# CH32H417 register map
Vendor: WCH Ltd.; File version: 1.2
Registers are 32-bit, read-write, reset 0x0 unless marked. A register's access mark holds for its fields unless they carry their own. Offsets are from the block's base; [hi:lo] are bit positions; {n}, {i} and the like mark numbered series.

## EXTI
Base 0x40010400
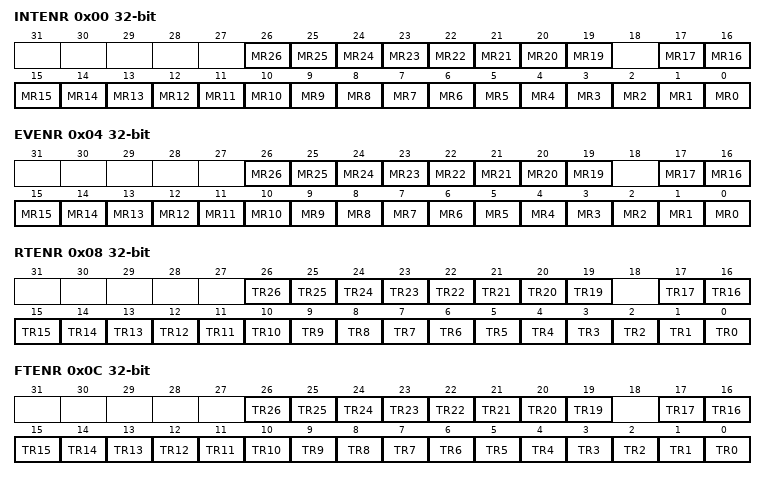
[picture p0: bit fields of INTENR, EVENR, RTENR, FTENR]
0x00 INTENR — Interrupt mask register (EXTI_INTENR)
  [n] MR{n} (n=19..26) — Interrupt Mask on line {n}
  [n] MR{n} (n=0..17) — Interrupt Mask on line {n}
0x04 EVENR — Event mask register (EXTI_EVENR)
  [n] MR{n} (n=19..26) — Event Mask on line {n}
  [n] MR{n} (n=0..17) — Event Mask on line {n}
0x08 RTENR — Rising Trigger selection register (EXTI_RTENR)
  [n] TR{n} (n=19..26) — Rising trigger event configuration of line {n}
  [n] TR{n} (n=0..17) — Rising trigger event configuration of line {n}
0x0C FTENR — Falling Trigger selection register (EXTI_FTENR)
  [n] TR{n} (n=19..26) — Falling trigger event configuration of line {n}
  [n] TR{n} (n=0..17) — Falling trigger event configuration of line {n}
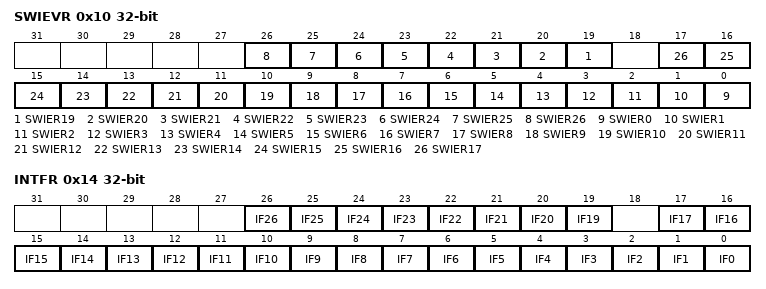
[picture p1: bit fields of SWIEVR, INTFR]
0x10 SWIEVR — Software interrupt event register (EXTI_SWIEVR)
  [n] SWIER{n} (n=19..26) — Software Interrupt on line {n}
  [n] SWIER{n} (n=0..17) — Software Interrupt on line {n}
0x14 INTFR — interrupt flag register (EXTI_INTFR)
  [n] IF{n} (n=19..26) — interrupt flag bit {n}
  [n] IF{n} (n=0..17) — interrupt flag bit {n}

## OPA — OPA configuration
Base 0x40017800
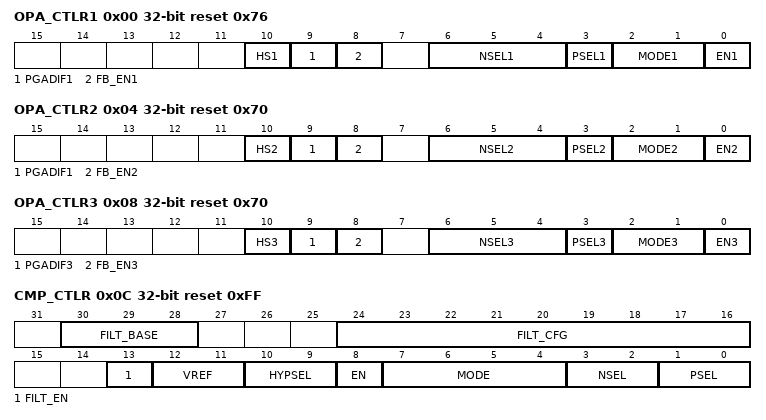
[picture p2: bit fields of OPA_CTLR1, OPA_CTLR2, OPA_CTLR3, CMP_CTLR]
0x00 OPA_CTLR1 reset 0x76 — OPA Control Register 1
  [10] HS1 — OPA1 high-speed mode enables
  [9] PGADIF1 — OPA1 is used with NSEL1 as PGA and the N-terminal is connected to OPA1_CHN1 (PA7)
  [8] FB_EN1 — OPA1's PGA mode feedback enable
  [6:4] NSEL1 — OPA1 Negative Channel Selection vs. PGA Gain Selection
  [3] PSEL1 — OPA1 Positive Channel Selection
  [2:1] MODE1 — OPA1 Output Channel Selection
  [0] EN1 — OPA1 enable
0x04 OPA_CTLR2 reset 0x70 — OPA Control Register 2
  [10] HS2 — OPA2 high-speed mode enables
  [9] PGADIF1 — OPA2 is used with NSEL1 as PGA and the N-terminal is connected to OPA2_CHN1 (PA7)
  [8] FB_EN2 — OPA2's PGA mode feedback enable
  [6:4] NSEL2 — OPA2 Negative Channel Selection vs. PGA Gain Selection
  [3] PSEL2 — OPA2 Positive Channel Selection
  [2:1] MODE2 — OPA2 Output Channel Selection
  [0] EN2 — OPA2 enable
0x08 OPA_CTLR3 reset 0x70 — OPA Control Register 3
  [10] HS3 — OPA3 high-speed mode enables
  [9] PGADIF3 — OPA3 is used with NSEL1 as PGA and the N-terminal is connected to OPA3_CHN1 (PA7)
  [8] FB_EN3 — OPA3's PGA mode feedback enable
  [6:4] NSEL3 — OPA3 Negative Channel Selection vs. PGA Gain Selection
  [3] PSEL3 — OPA3 Positive Channel Selection
  [2:1] MODE3 — OPA3 Output Channel Selection
  [0] EN3 — OPA3 enable
0x0C CMP_CTLR reset 0xFF — CMP Control Registers
  [30:28] FILT_BASE — CMP filtering sampling time base configuration
  [24:16] FILT_CFG — CMP filter sampling interval configuration
  [13] FILT_EN — CMP Digital Filtering Enable
  [12:11] VREF — CMP Internal Bias Voltage Selector
  [10:9] HYPSEL — CMP hysteresis voltage selector
  [8] EN — CMP enables
  [7:4] MODE — CMP Output Channel Selection
  [3:2] NSEL — CMP Negative End Channel Selection Bits
  [1:0] PSEL — CMP Positive Channel Selection Bits
0x10 CMP_STATR ro — CMP Status Registers
  [0] OUT_FILT — CMP Output

## QSPI1
Base 0x40024C00
Same registers: QSPI2 0x40025000
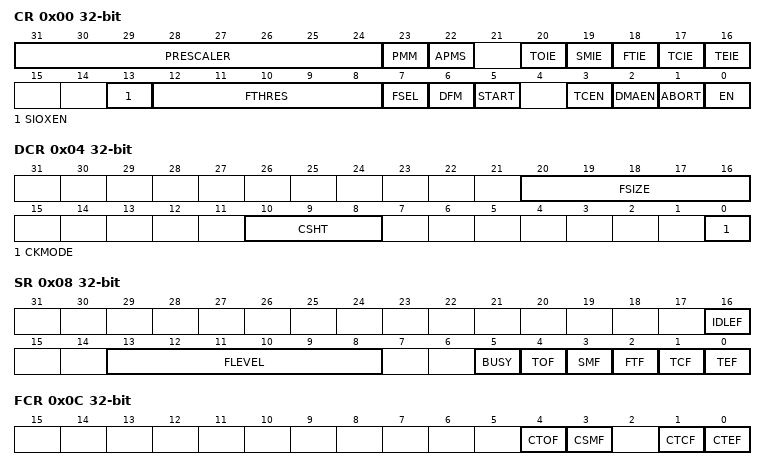
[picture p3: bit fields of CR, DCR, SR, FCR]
0x00 CR access per field — QSPI control register
  [31:24] PRESCALER rw — clock prescaler
  [23] PMM rw — Polling match mode
  [22] APMS rw — Automatic poll mode stop
  [20] TOIE rw — TimeOut interrupt enable This bit enables the TimeOut interrupt.
  [19] SMIE rw — Status match interrupt enable This bit enables the status match interrupt.
  [18] FTIE rw — FIFO threshold interrupt enable This bit enables the FIFO threshold interrupt.
  [17] TCIE rw — Transfer complete interrupt enable This bit enables the transfer complete interrupt.
  [16] TEIE rw — Transfer error interrupt enable This bit enables the transfer error interrupt.
  [13] SIOXEN rw — SIOX enable
  [12:8] FTHRES rw — FIFO threshold level Defines
  [7] FSEL rw — Flash memory selection
  [6] DFM rw — Dual-flash mode This bit activates dual-flash mode
  [5] START wo — start the FLASH command sequence
  [3] TCEN rw — Timeout counter enable
  [2] DMAEN rw — DMA mode enabled
  [1] ABORT rw — Abort request This bit aborts the on-going command sequence
  [0] EN rw — Enable Enable the QSPI
0x04 DCR — QSPI device configuration register
  [20:16] FSIZE — Flash memory size
  [10:8] CSHT — Chip select high time
  [0] CKMODE — indicates the level that clk takes between command
0x08 SR ro — QSPI status register
  [16] IDLEF — IDLE flag
  [13:8] FLEVEL — FIFO level
  [5] BUSY — Busy This bit is set when an operation is on going
  [4] TOF — Timeout flag This bit is set when timeout occurs
  [3] SMF — Status match flag
  [2] FTF — FIFO threshold flag
  [1] TCF — Transfer complete flag
  [0] TEF — Transfer error flag
0x0C FCR — QSPI flag clear register
  [4] CTOF — Clear timeout flag Writing 1 clears the TOF flag in the QSPI_SR register
  [3] CSMF — Clear status match flag Writing 1 clears the SMF flag in the QSPI_SR register
  [1] CTCF — Clear transfer complete flag Writing 1 clears the TCF flag in the QSPI_SR register
  [0] CTEF — Clear transfer error flag Writing 1 clears the TEF flag in the QSPI_SR register
0x10 DLR — QSPI data length register
  [31:0] DL — Data length
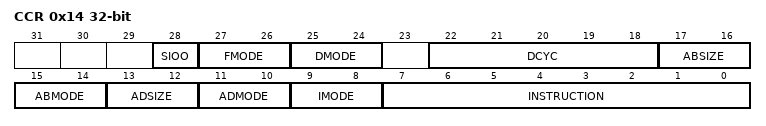
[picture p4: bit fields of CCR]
0x14 CCR — QSPI communication configuration register
  [28] SIOO — Send instruction only once mode
  [27:26] FMODE — Functional mode
  [25:24] DMODE — Data mode
  [22:18] DCYC — Number of dummy cycles
  [17:16] ABSIZE — Alternate bytes size
  [15:14] ABMODE — Alternate bytes mode
  [13:12] ADSIZE — Address size
  [11:10] ADMODE — Address mode
  [9:8] IMODE — Instruction mode
  [7:0] INSTRUCTION
0x18 AR — QSPI address register
  [31:0] ADDRESS — QSPI Address
0x1C ABR — QSPI alternate bytes registers
  [31:0] ALTERNATE — Alternate Bytes Optional data to be send to the external SPI device right after the address.
0x20 DR — QSPI data register
  [31:0] DATA
0x24 PSMKR — QSPI polling status mask register
  [31:0] MASK — Status mask Mask to be applied to the status bytes received in polling mode
0x28 PSMAR — QSPI polling status match register
  [31:0] MATCH — Status match Value to be compared with the masked status register to get a match. This field can be written only when BUSY = 0.
0x2C PIR — QSPI polling interval register
  [15:0] INTERVAL — Polling interval Number of CLK cycles between to read during automatic polling phases. This field can be written only when BUSY = 0.
0x30 LPTR — QSPI low-power timeout register
  [15:0] TIMEOUT
